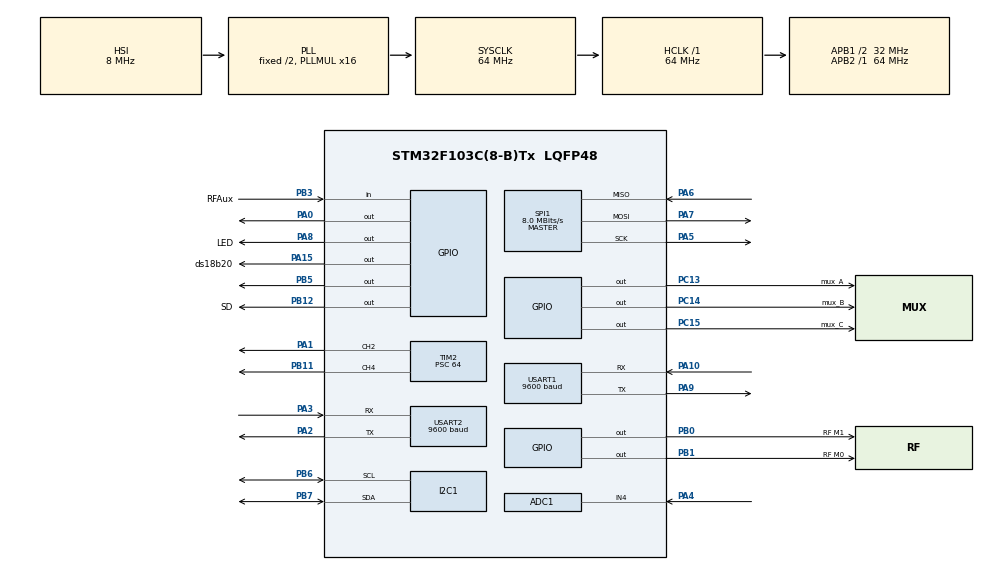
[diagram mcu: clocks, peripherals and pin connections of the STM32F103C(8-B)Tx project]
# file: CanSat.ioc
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ADC1.Channel-1\#ChannelRegularConversion=ADC_CHANNEL_4
ADC1.NbrOfConversionFlag=1
ADC1.Rank-1\#ChannelRegularConversion=1
ADC1.SamplingTime-1\#ChannelRegularConversion=ADC_SAMPLETIME_1CYCLE_5
ADC1.master=1
FATFS._MAX_SS=4096
FATFS._USE_LFN=1
Mcu.Family=STM32F1
Mcu.Name=STM32F103C(8-B)Tx
Mcu.Package=LQFP48
NVIC.PriorityGroup=NVIC_PRIORITYGROUP_4
NVIC.USART1_IRQn=true\:0\:0\:false\:false\:true\:true\:false\:true
PA0-WKUP.Signal=GPIO_Output
PA1.Signal=S_TIM2_CH2
PA10.Mode=Asynchronous
PA10.Signal=USART1_RX
PA13.Mode=Serial_Wire
PA13.Signal=SYS_JTMS-SWDIO
PA14.Mode=Serial_Wire
PA14.Signal=SYS_JTCK-SWCLK
PA15.GPIO_Label=ds18b20
PA15.GPIO_ModeDefaultOutputPP=GPIO_MODE_OUTPUT_OD
PA15.GPIO_PuPd=GPIO_NOPULL
PA15.Signal=GPIO_Output
PA2.Mode=Asynchronous
PA2.Signal=USART2_TX
PA3.Mode=Asynchronous
PA3.Signal=USART2_RX
PA4.Signal=ADCx_IN4
PA5.Mode=Full_Duplex_Master
PA5.Signal=SPI1_SCK
PA6.Mode=Full_Duplex_Master
PA6.Signal=SPI1_MISO
PA7.Mode=Full_Duplex_Master
PA7.Signal=SPI1_MOSI
PA8.GPIO_Label=LED
PA8.GPIO_ModeDefaultOutputPP=GPIO_MODE_OUTPUT_PP
PA8.GPIO_PuPd=GPIO_NOPULL
PA8.Signal=GPIO_Output
PA9.Mode=Asynchronous
PA9.Signal=USART1_TX
PB0.GPIO_Label=RF M1
PB0.Signal=GPIO_Output
PB1.GPIO_Label=RF M0
PB1.Signal=GPIO_Output
PB11.Signal=S_TIM2_CH4
PB12.GPIO_Label=SD
PB12.Signal=GPIO_Output
PB3.GPIO_Label=RFAux
PB3.Signal=GPIO_Input
PB5.Signal=GPIO_Output
PB6.Mode=I2C
PB6.Signal=I2C1_SCL
PB7.Mode=I2C
PB7.Signal=I2C1_SDA
PC13-TAMPER-RTC.GPIO_Label=mux_A
PC13-TAMPER-RTC.Signal=GPIO_Output
PC14-OSC32_IN.GPIO_Label=mux_B
PC14-OSC32_IN.Signal=GPIO_Output
PC15-OSC32_OUT.GPIO_Label=mux_C
PC15-OSC32_OUT.Signal=GPIO_Output
ProjectManager.HeapSize=0x200
ProjectManager.StackSize=0x400
ProjectManager.TargetToolchain=STM32CubeIDE
RCC.ADCPresc=RCC_ADCPCLK2_DIV6
RCC.AHBFreq_Value=64000000
RCC.APB1CLKDivider=RCC_HCLK_DIV2
RCC.APB1Freq_Value=32000000
RCC.APB1TimFreq_Value=64000000
RCC.APB2Freq_Value=64000000
RCC.APB2TimFreq_Value=64000000
RCC.HCLKFreq_Value=64000000
RCC.PLLMUL=RCC_PLL_MUL16
RCC.SYSCLKFreq_VALUE=64000000
RCC.SYSCLKSource=RCC_SYSCLKSOURCE_PLLCLK
RCC.USBFreq_Value=64000000
SH.ADCx_IN4.0=ADC1_IN4,IN4
SH.S_TIM2_CH2.0=TIM2_CH2,PWM Generation2 CH2
SH.S_TIM2_CH4.0=TIM2_CH4,PWM Generation4 CH4
SPI1.BaudRatePrescaler=SPI_BAUDRATEPRESCALER_8
SPI1.CalculateBaudRate=8.0 MBits/s
SPI1.Direction=SPI_DIRECTION_2LINES
SPI1.Mode=SPI_MODE_MASTER
SPI1.VirtualType=VM_MASTER
TIM1.AutoReloadPreload=TIM_AUTORELOAD_PRELOAD_ENABLE
TIM1.Prescaler=63
TIM2.Channel-PWM\ Generation2\ CH2=TIM_CHANNEL_2
TIM2.Channel-PWM\ Generation4\ CH4=TIM_CHANNEL_4
TIM2.Period=20000
TIM2.Prescaler=64
TIM2.Pulse-PWM\ Generation2\ CH2=1500
TIM2.Pulse-PWM\ Generation4\ CH4=1500
USART1.BaudRate=9600
USART1.VirtualMode=VM_ASYNC
USART2.BaudRate=9600
USART2.VirtualMode=VM_ASYNC
VP_FATFS_VS_Generic.Mode=User_defined
VP_TIM1_VS_ClockSourceINT.Mode=Internal
VP_TIM2_VS_ClockSourceINT.Mode=Internal
board=custom

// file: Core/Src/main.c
/* USER CODE BEGIN Header */
/**
  ******************************************************************************
  * @file           : main.c
  * @brief          : Main program body
  ******************************************************************************
  * @attention
  *
  * Copyright (c) 2026 STMicroelectronics.
  * All rights reserved.
  *
  * This software is licensed under terms that can be found in the LICENSE file
  * in the root directory of this software component.
  * If no LICENSE file comes with this software, it is provided AS-IS.
  *
  ******************************************************************************
  */
/* USER CODE END Header */
#include "main.h"
#include "fatfs.h"

ADC_HandleTypeDef hadc1;

I2C_HandleTypeDef hi2c1;

SPI_HandleTypeDef hspi1;

TIM_HandleTypeDef htim1;
TIM_HandleTypeDef htim2;

UART_HandleTypeDef huart1;
UART_HandleTypeDef huart2;

void SystemClock_Config(void);
static void MX_GPIO_Init(void);
static void MX_USART1_UART_Init(void);
static void MX_USART2_UART_Init(void);
static void MX_I2C1_Init(void);
static void MX_SPI1_Init(void);
static void MX_ADC1_Init(void);
static void MX_TIM2_Init(void);
static void MX_TIM1_Init(void);

/* USER CODE BEGIN 0 */
void appMain();
/* USER CODE END 0 */

int main(void)
{

  /* USER CODE BEGIN 1 */
//   volatile int x;
//   for (size_t i = 0; i < 2000; i++)
//	   x = 0;
  /* USER CODE END 1 */

  /* MCU Configuration--------------------------------------------------------*/

  /* Reset of all peripherals, Initializes the Flash interface and the Systick. */
  HAL_Init();

  /* Configure the system clock */
  SystemClock_Config();

  /* Initialize all configured peripherals */
  MX_GPIO_Init();
  MX_USART1_UART_Init();
  MX_USART2_UART_Init();
  MX_I2C1_Init();
  MX_SPI1_Init();
  MX_FATFS_Init();
  MX_ADC1_Init();
  MX_TIM2_Init();
  MX_TIM1_Init();

  /* Infinite loop */
  /* USER CODE BEGIN WHILE */
  while (1)
  {
	  appMain();
    /* USER CODE END WHILE */

  }
}

void SystemClock_Config(void)
{
  RCC_OscInitTypeDef RCC_OscInitStruct = {0};
  RCC_ClkInitTypeDef RCC_ClkInitStruct = {0};
  RCC_PeriphCLKInitTypeDef PeriphClkInit = {0};

  /** Initializes the RCC Oscillators according to the specified parameters
  * in the RCC_OscInitTypeDef structure.
  */
  RCC_OscInitStruct.OscillatorType = RCC_OSCILLATORTYPE_HSI;
  RCC_OscInitStruct.HSIState = RCC_HSI_ON;
  RCC_OscInitStruct.HSICalibrationValue = RCC_HSICALIBRATION_DEFAULT;
  RCC_OscInitStruct.PLL.PLLState = RCC_PLL_ON;
  RCC_OscInitStruct.PLL.PLLSource = RCC_PLLSOURCE_HSI_DIV2;
  RCC_OscInitStruct.PLL.PLLMUL = RCC_PLL_MUL16;
  if (HAL_RCC_OscConfig(&RCC_OscInitStruct) != HAL_OK)
  {
    Error_Handler();
  }

  /** Initializes the CPU, AHB and APB buses clocks
  */
  RCC_ClkInitStruct.ClockType = RCC_CLOCKTYPE_HCLK|RCC_CLOCKTYPE_SYSCLK
                              |RCC_CLOCKTYPE_PCLK1|RCC_CLOCKTYPE_PCLK2;
  RCC_ClkInitStruct.SYSCLKSource = RCC_SYSCLKSOURCE_PLLCLK;
  RCC_ClkInitStruct.AHBCLKDivider = RCC_SYSCLK_DIV1;
  RCC_ClkInitStruct.APB1CLKDivider = RCC_HCLK_DIV2;
  RCC_ClkInitStruct.APB2CLKDivider = RCC_HCLK_DIV1;

  if (HAL_RCC_ClockConfig(&RCC_ClkInitStruct, FLASH_LATENCY_2) != HAL_OK)
  {
    Error_Handler();
  }
  PeriphClkInit.PeriphClockSelection = RCC_PERIPHCLK_ADC;
  PeriphClkInit.AdcClockSelection = RCC_ADCPCLK2_DIV6;
  if (HAL_RCCEx_PeriphCLKConfig(&PeriphClkInit) != HAL_OK)
  {
    Error_Handler();
  }
}

static void MX_ADC1_Init(void)
{

  ADC_ChannelConfTypeDef sConfig = {0};

  /** Common config
  */
  hadc1.Instance = ADC1;
  hadc1.Init.ScanConvMode = ADC_SCAN_DISABLE;
  hadc1.Init.ContinuousConvMode = DISABLE;
  hadc1.Init.DiscontinuousConvMode = DISABLE;
  hadc1.Init.ExternalTrigConv = ADC_SOFTWARE_START;
  hadc1.Init.DataAlign = ADC_DATAALIGN_RIGHT;
  hadc1.Init.NbrOfConversion = 1;
  if (HAL_ADC_Init(&hadc1) != HAL_OK)
  {
    Error_Handler();
  }

  /** Configure Regular Channel
  */
  sConfig.Channel = ADC_CHANNEL_4;
  sConfig.Rank = ADC_REGULAR_RANK_1;
  sConfig.SamplingTime = ADC_SAMPLETIME_1CYCLE_5;
  if (HAL_ADC_ConfigChannel(&hadc1, &sConfig) != HAL_OK)
  {
    Error_Handler();
  }

}

static void MX_I2C1_Init(void)
{

  hi2c1.Instance = I2C1;
  hi2c1.Init.ClockSpeed = 100000;
  hi2c1.Init.DutyCycle = I2C_DUTYCYCLE_2;
  hi2c1.Init.OwnAddress1 = 0;
  hi2c1.Init.AddressingMode = I2C_ADDRESSINGMODE_7BIT;
  hi2c1.Init.DualAddressMode = I2C_DUALADDRESS_DISABLE;
  hi2c1.Init.OwnAddress2 = 0;
  hi2c1.Init.GeneralCallMode = I2C_GENERALCALL_DISABLE;
  hi2c1.Init.NoStretchMode = I2C_NOSTRETCH_DISABLE;
  if (HAL_I2C_Init(&hi2c1) != HAL_OK)
  {
    Error_Handler();
  }

}

static void MX_SPI1_Init(void)
{

  /* SPI1 parameter configuration*/
  hspi1.Instance = SPI1;
  hspi1.Init.Mode = SPI_MODE_MASTER;
  hspi1.Init.Direction = SPI_DIRECTION_2LINES;
  hspi1.Init.DataSize = SPI_DATASIZE_8BIT;
  hspi1.Init.CLKPolarity = SPI_POLARITY_LOW;
  hspi1.Init.CLKPhase = SPI_PHASE_1EDGE;
  hspi1.Init.NSS = SPI_NSS_SOFT;
  hspi1.Init.BaudRatePrescaler = SPI_BAUDRATEPRESCALER_8;
  hspi1.Init.FirstBit = SPI_FIRSTBIT_MSB;
  hspi1.Init.TIMode = SPI_TIMODE_DISABLE;
  hspi1.Init.CRCCalculation = SPI_CRCCALCULATION_DISABLE;
  hspi1.Init.CRCPolynomial = 10;
  if (HAL_SPI_Init(&hspi1) != HAL_OK)
  {
    Error_Handler();
  }

}

static void MX_TIM1_Init(void)
{

  TIM_ClockConfigTypeDef sClockSourceConfig = {0};
  TIM_MasterConfigTypeDef sMasterConfig = {0};

  htim1.Instance = TIM1;
  htim1.Init.Prescaler = 63;
  htim1.Init.CounterMode = TIM_COUNTERMODE_UP;
  htim1.Init.Period = 65535;
  htim1.Init.ClockDivision = TIM_CLOCKDIVISION_DIV1;
  htim1.Init.RepetitionCounter = 0;
  htim1.Init.AutoReloadPreload = TIM_AUTORELOAD_PRELOAD_ENABLE;
  if (HAL_TIM_Base_Init(&htim1) != HAL_OK)
  {
    Error_Handler();
  }
  sClockSourceConfig.ClockSource = TIM_CLOCKSOURCE_INTERNAL;
  if (HAL_TIM_ConfigClockSource(&htim1, &sClockSourceConfig) != HAL_OK)
  {
    Error_Handler();
  }
  sMasterConfig.MasterOutputTrigger = TIM_TRGO_RESET;
  sMasterConfig.MasterSlaveMode = TIM_MASTERSLAVEMODE_DISABLE;
  if (HAL_TIMEx_MasterConfigSynchronization(&htim1, &sMasterConfig) != HAL_OK)
  {
    Error_Handler();
  }

}

static void MX_TIM2_Init(void)
{

  TIM_ClockConfigTypeDef sClockSourceConfig = {0};
  TIM_MasterConfigTypeDef sMasterConfig = {0};
  TIM_OC_InitTypeDef sConfigOC = {0};

  htim2.Instance = TIM2;
  htim2.Init.Prescaler = 64;
  htim2.Init.CounterMode = TIM_COUNTERMODE_UP;
  htim2.Init.Period = 20000;
  htim2.Init.ClockDivision = TIM_CLOCKDIVISION_DIV1;
  htim2.Init.AutoReloadPreload = TIM_AUTORELOAD_PRELOAD_DISABLE;
  if (HAL_TIM_Base_Init(&htim2) != HAL_OK)
  {
    Error_Handler();
  }
  sClockSourceConfig.ClockSource = TIM_CLOCKSOURCE_INTERNAL;
  if (HAL_TIM_ConfigClockSource(&htim2, &sClockSourceConfig) != HAL_OK)
  {
    Error_Handler();
  }
  if (HAL_TIM_PWM_Init(&htim2) != HAL_OK)
  {
    Error_Handler();
  }
  sMasterConfig.MasterOutputTrigger = TIM_TRGO_RESET;
  sMasterConfig.MasterSlaveMode = TIM_MASTERSLAVEMODE_DISABLE;
  if (HAL_TIMEx_MasterConfigSynchronization(&htim2, &sMasterConfig) != HAL_OK)
  {
    Error_Handler();
  }
  sConfigOC.OCMode = TIM_OCMODE_PWM1;
  sConfigOC.Pulse = 1500;
  sConfigOC.OCPolarity = TIM_OCPOLARITY_HIGH;
  sConfigOC.OCFastMode = TIM_OCFAST_DISABLE;
  if (HAL_TIM_PWM_ConfigChannel(&htim2, &sConfigOC, TIM_CHANNEL_2) != HAL_OK)
  {
    Error_Handler();
  }
  if (HAL_TIM_PWM_ConfigChannel(&htim2, &sConfigOC, TIM_CHANNEL_4) != HAL_OK)
  {
    Error_Handler();
  }
  HAL_TIM_MspPostInit(&htim2);

}

static void MX_USART1_UART_Init(void)
{

  huart1.Instance = USART1;
  huart1.Init.BaudRate = 9600;
  huart1.Init.WordLength = UART_WORDLENGTH_8B;
  huart1.Init.StopBits = UART_STOPBITS_1;
  huart1.Init.Parity = UART_PARITY_NONE;
  huart1.Init.Mode = UART_MODE_TX_RX;
  huart1.Init.HwFlowCtl = UART_HWCONTROL_NONE;
  huart1.Init.OverSampling = UART_OVERSAMPLING_16;
  if (HAL_UART_Init(&huart1) != HAL_OK)
  {
    Error_Handler();
  }

}

static void MX_USART2_UART_Init(void)
{

  huart2.Instance = USART2;
  huart2.Init.BaudRate = 9600;
  huart2.Init.WordLength = UART_WORDLENGTH_8B;
  huart2.Init.StopBits = UART_STOPBITS_1;
  huart2.Init.Parity = UART_PARITY_NONE;
  huart2.Init.Mode = UART_MODE_TX_RX;
  huart2.Init.HwFlowCtl = UART_HWCONTROL_NONE;
  huart2.Init.OverSampling = UART_OVERSAMPLING_16;
  if (HAL_UART_Init(&huart2) != HAL_OK)
  {
    Error_Handler();
  }

}

static void MX_GPIO_Init(void)
{
  GPIO_InitTypeDef GPIO_InitStruct = {0};

  /* GPIO Ports Clock Enable */
  __HAL_RCC_GPIOC_CLK_ENABLE();
  __HAL_RCC_GPIOA_CLK_ENABLE();
  __HAL_RCC_GPIOB_CLK_ENABLE();

  /*Configure GPIO pin Output Level */
  HAL_GPIO_WritePin(GPIOC, mux_A_Pin|mux_B_Pin|mux_C_Pin, GPIO_PIN_RESET);

  /*Configure GPIO pin Output Level */
  HAL_GPIO_WritePin(GPIOA, GPIO_PIN_0|LED_Pin|ds18b20_Pin, GPIO_PIN_RESET);

  /*Configure GPIO pin Output Level */
  HAL_GPIO_WritePin(GPIOB, RF_M1_Pin|RF_M0_Pin|SD_Pin|GPIO_PIN_5, GPIO_PIN_RESET);

  /*Configure GPIO pins : mux_A_Pin mux_B_Pin mux_C_Pin */
  GPIO_InitStruct.Pin = mux_A_Pin|mux_B_Pin|mux_C_Pin;
  GPIO_InitStruct.Mode = GPIO_MODE_OUTPUT_PP;
  GPIO_InitStruct.Pull = GPIO_NOPULL;
  GPIO_InitStruct.Speed = GPIO_SPEED_FREQ_LOW;
  HAL_GPIO_Init(GPIOC, &GPIO_InitStruct);

  /*Configure GPIO pins : PA0 LED_Pin */
  GPIO_InitStruct.Pin = GPIO_PIN_0|LED_Pin;
  GPIO_InitStruct.Mode = GPIO_MODE_OUTPUT_PP;
  GPIO_InitStruct.Pull = GPIO_NOPULL;
  GPIO_InitStruct.Speed = GPIO_SPEED_FREQ_LOW;
  HAL_GPIO_Init(GPIOA, &GPIO_InitStruct);

  /*Configure GPIO pins : RF_M1_Pin RF_M0_Pin SD_Pin PB5 */
  GPIO_InitStruct.Pin = RF_M1_Pin|RF_M0_Pin|SD_Pin|GPIO_PIN_5;
  GPIO_InitStruct.Mode = GPIO_MODE_OUTPUT_PP;
  GPIO_InitStruct.Pull = GPIO_NOPULL;
  GPIO_InitStruct.Speed = GPIO_SPEED_FREQ_LOW;
  HAL_GPIO_Init(GPIOB, &GPIO_InitStruct);

  /*Configure GPIO pin : ds18b20_Pin */
  GPIO_InitStruct.Pin = ds18b20_Pin;
  GPIO_InitStruct.Mode = GPIO_MODE_OUTPUT_OD;
  GPIO_InitStruct.Pull = GPIO_NOPULL;
  GPIO_InitStruct.Speed = GPIO_SPEED_FREQ_LOW;
  HAL_GPIO_Init(ds18b20_GPIO_Port, &GPIO_InitStruct);

  /*Configure GPIO pin : RFAux_Pin */
  GPIO_InitStruct.Pin = RFAux_Pin;
  GPIO_InitStruct.Mode = GPIO_MODE_INPUT;
  GPIO_InitStruct.Pull = GPIO_NOPULL;
  HAL_GPIO_Init(RFAux_GPIO_Port, &GPIO_InitStruct);

}

void Error_Handler(void)
{
  __disable_irq();
  while (1)
  {
  }
}
